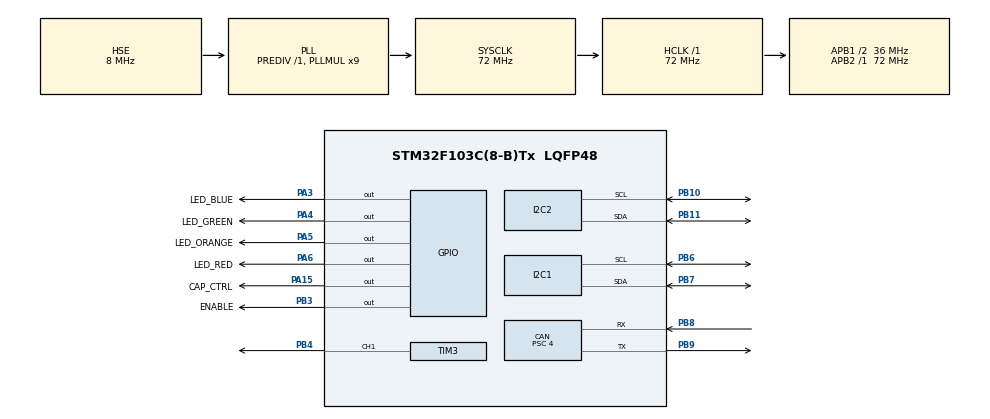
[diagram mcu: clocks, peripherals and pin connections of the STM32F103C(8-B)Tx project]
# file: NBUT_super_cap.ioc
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CAN.ABOM=ENABLE
CAN.BS1=CAN_BS1_4TQ
CAN.BS2=CAN_BS2_4TQ
CAN.CalculateBaudRate=1000000
CAN.CalculateTimeBit=1000
CAN.CalculateTimeQuantum=111.11111111111111
CAN.Prescaler=4
FREERTOS.Tasks01=communicate,2,128,communicate_task,Default,NULL,Dynamic,NULL,NULL;cap_ctrl,2,128,cap_ctrl_task,Default,NULL,Dynamic,NULL,NULL
Mcu.Family=STM32F1
Mcu.Name=STM32F103C(8-B)Tx
Mcu.Package=LQFP48
NVIC.CAN1_RX1_IRQn=true\:5\:0\:false\:false\:true\:true\:true\:true\:true
NVIC.I2C1_EV_IRQn=true\:5\:0\:false\:false\:true\:true\:true\:true\:true
NVIC.I2C2_EV_IRQn=true\:5\:0\:false\:false\:true\:true\:true\:true\:true
NVIC.PriorityGroup=NVIC_PRIORITYGROUP_4
NVIC.TIM3_IRQn=true\:5\:0\:false\:false\:true\:true\:true\:true\:true
NVIC.USB_LP_CAN1_RX0_IRQn=true\:5\:0\:false\:false\:true\:true\:true\:true\:true
PA13.Mode=Serial_Wire
PA13.Signal=SYS_JTMS-SWDIO
PA14.Mode=Serial_Wire
PA14.Signal=SYS_JTCK-SWCLK
PA15.GPIO_Label=CAP_CTRL
PA15.Signal=GPIO_Output
PA3.GPIO_Label=LED_BLUE
PA3.GPIO_PuPd=GPIO_PULLDOWN
PA3.Signal=GPIO_Output
PA4.GPIO_Label=LED_GREEN
PA4.GPIO_PuPd=GPIO_PULLDOWN
PA4.Signal=GPIO_Output
PA5.GPIO_Label=LED_ORANGE
PA5.GPIO_PuPd=GPIO_PULLDOWN
PA5.Signal=GPIO_Output
PA6.GPIO_Label=LED_RED
PA6.GPIO_PuPd=GPIO_PULLDOWN
PA6.Signal=GPIO_Output
PB10.Mode=I2C
PB10.Signal=I2C2_SCL
PB11.Mode=I2C
PB11.Signal=I2C2_SDA
PB3.GPIO_Label=ENABLE
PB3.Signal=GPIO_Output
PB4.Signal=S_TIM3_CH1
PB6.Mode=I2C
PB6.Signal=I2C1_SCL
PB7.Mode=I2C
PB7.Signal=I2C1_SDA
PB8.Mode=CAN_Activate
PB8.Signal=CAN_RX
PB9.Mode=CAN_Activate
PB9.Signal=CAN_TX
PD0-OSC_IN.Mode=HSE-External-Oscillator
PD0-OSC_IN.Signal=RCC_OSC_IN
PD1-OSC_OUT.Mode=HSE-External-Oscillator
PD1-OSC_OUT.Signal=RCC_OSC_OUT
ProjectManager.HeapSize=0x200
ProjectManager.StackSize=0x400
ProjectManager.TargetToolchain=MDK-ARM V5.32
RCC.AHBFreq_Value=72000000
RCC.APB1CLKDivider=RCC_HCLK_DIV2
RCC.APB1Freq_Value=36000000
RCC.APB1TimFreq_Value=72000000
RCC.APB2Freq_Value=72000000
RCC.APB2TimFreq_Value=72000000
RCC.HCLKFreq_Value=72000000
RCC.PLLMUL=RCC_PLL_MUL9
RCC.PLLSourceVirtual=RCC_PLLSOURCE_HSE
RCC.SYSCLKFreq_VALUE=72000000
RCC.SYSCLKSource=RCC_SYSCLKSOURCE_PLLCLK
RCC.USBFreq_Value=72000000
SH.S_TIM3_CH1.0=TIM3_CH1,PWM Generation1 CH1
TIM3.Channel-PWM\ Generation1\ CH1=TIM_CHANNEL_1
TIM3.Period=999
TIM3.Prescaler=35
VP_FREERTOS_VS_CMSIS_V1.Mode=CMSIS_V1
VP_TIM3_VS_ClockSourceINT.Mode=Internal
board=custom

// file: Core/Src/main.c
/* USER CODE BEGIN Header */
/**
  ******************************************************************************
  * @file           : main.c
  * @brief          : Main program body
  ******************************************************************************
  * @attention
  *
  * Copyright (c) 2022 STMicroelectronics.
  * All rights reserved.
  *
  * This software is licensed under terms that can be found in the LICENSE file
  * in the root directory of this software component.
  * If no LICENSE file comes with this software, it is provided AS-IS.
  *
  ******************************************************************************
  */
/* USER CODE END Header */
#include "main.h"
#include "cmsis_os.h"
#include "can.h"
#include "i2c.h"
#include "tim.h"
#include "gpio.h"

/* USER CODE BEGIN Includes */
#include "bsp_ina226.h"
#include "bsp_LM5106.h"
#include "bsp_led.h"
/* USER CODE END Includes */

void SystemClock_Config(void);
void MX_FREERTOS_Init(void);

int main(void)
{

  /* MCU Configuration--------------------------------------------------------*/

  /* Reset of all peripherals, Initializes the Flash interface and the Systick. */
  HAL_Init();

  /* Configure the system clock */
  SystemClock_Config();

  /* Initialize all configured peripherals */
  MX_GPIO_Init();
  MX_CAN_Init();
  MX_I2C1_Init();
  MX_I2C2_Init();
  MX_TIM3_Init();
  /* USER CODE BEGIN 2 */
  INA226_Init();
  LED_Init();
	Cap_Charge_LED_On();
  /* USER CODE END 2 */

  /* Call init function for freertos objects (in freertos.c) */
  MX_FREERTOS_Init();

  /* Start scheduler */
  osKernelStart();

  /* We should never get here as control is now taken by the scheduler */
  /* Infinite loop */
  while (1)
  {

  }
}

void SystemClock_Config(void)
{
  RCC_OscInitTypeDef RCC_OscInitStruct = {0};
  RCC_ClkInitTypeDef RCC_ClkInitStruct = {0};

  /** Initializes the RCC Oscillators according to the specified parameters
  * in the RCC_OscInitTypeDef structure.
  */
  RCC_OscInitStruct.OscillatorType = RCC_OSCILLATORTYPE_HSE;
  RCC_OscInitStruct.HSEState = RCC_HSE_ON;
  RCC_OscInitStruct.HSEPredivValue = RCC_HSE_PREDIV_DIV1;
  RCC_OscInitStruct.HSIState = RCC_HSI_ON;
  RCC_OscInitStruct.PLL.PLLState = RCC_PLL_ON;
  RCC_OscInitStruct.PLL.PLLSource = RCC_PLLSOURCE_HSE;
  RCC_OscInitStruct.PLL.PLLMUL = RCC_PLL_MUL9;
  if (HAL_RCC_OscConfig(&RCC_OscInitStruct) != HAL_OK)
  {
    Error_Handler();
  }

  /** Initializes the CPU, AHB and APB buses clocks
  */
  RCC_ClkInitStruct.ClockType = RCC_CLOCKTYPE_HCLK|RCC_CLOCKTYPE_SYSCLK
                              |RCC_CLOCKTYPE_PCLK1|RCC_CLOCKTYPE_PCLK2;
  RCC_ClkInitStruct.SYSCLKSource = RCC_SYSCLKSOURCE_PLLCLK;
  RCC_ClkInitStruct.AHBCLKDivider = RCC_SYSCLK_DIV1;
  RCC_ClkInitStruct.APB1CLKDivider = RCC_HCLK_DIV2;
  RCC_ClkInitStruct.APB2CLKDivider = RCC_HCLK_DIV1;

  if (HAL_RCC_ClockConfig(&RCC_ClkInitStruct, FLASH_LATENCY_2) != HAL_OK)
  {
    Error_Handler();
  }
}

void Error_Handler(void)
{
  __disable_irq();
 while (1)
  {
  }
}

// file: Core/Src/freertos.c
/* USER CODE BEGIN Header */
/**
  ******************************************************************************
  * File Name          : freertos.c
  * Description        : Code for freertos applications
  ******************************************************************************
  * @attention
  *
  * Copyright (c) 2022 STMicroelectronics.
  * All rights reserved.
  *
  * This software is licensed under terms that can be found in the LICENSE file
  * in the root directory of this software component.
  * If no LICENSE file comes with this software, it is provided AS-IS.
  *
  ******************************************************************************
  */
/* USER CODE END Header */

#include "FreeRTOS.h"
#include "task.h"
#include "main.h"
#include "cmsis_os.h"

osThreadId communicateHandle;
osThreadId cap_ctrlHandle;

void communicate_task(void const * argument);
void cap_ctrl_task(void const * argument);

void MX_FREERTOS_Init(void); /* (MISRA C 2004 rule 8.1) */

/* GetIdleTaskMemory prototype (linked to static allocation support) */
void vApplicationGetIdleTaskMemory( StaticTask_t **ppxIdleTaskTCBBuffer, StackType_t **ppxIdleTaskStackBuffer, uint32_t *pulIdleTaskStackSize );

/* USER CODE BEGIN GET_IDLE_TASK_MEMORY */
static StaticTask_t xIdleTaskTCBBuffer;
static StackType_t xIdleStack[configMINIMAL_STACK_SIZE];

void vApplicationGetIdleTaskMemory( StaticTask_t **ppxIdleTaskTCBBuffer, StackType_t **ppxIdleTaskStackBuffer, uint32_t *pulIdleTaskStackSize )
{
  *ppxIdleTaskTCBBuffer = &xIdleTaskTCBBuffer;
  *ppxIdleTaskStackBuffer = &xIdleStack[0];
  *pulIdleTaskStackSize = configMINIMAL_STACK_SIZE;
  /* place for user code */
}
/* USER CODE END GET_IDLE_TASK_MEMORY */

void MX_FREERTOS_Init(void) {

  /* Create the thread(s) */
  /* definition and creation of communicate */
  osThreadDef(communicate, communicate_task, osPriorityHigh, 0, 128);
  communicateHandle = osThreadCreate(osThread(communicate), NULL);

  /* definition and creation of cap_ctrl */
  osThreadDef(cap_ctrl, cap_ctrl_task, osPriorityHigh, 0, 128);
  cap_ctrlHandle = osThreadCreate(osThread(cap_ctrl), NULL);

}
